VERSION ""

NS_ :

BS_:

BU_: VCU BMS INV ABS SENSOR_GATEWAY CHARGER DIAG RCM OCCUPANT_SENSOR

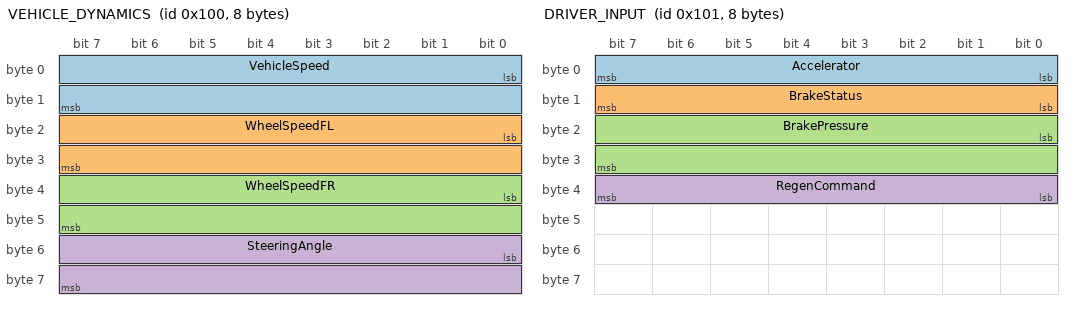
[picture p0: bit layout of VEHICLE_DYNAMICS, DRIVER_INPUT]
BO_ 256 VEHICLE_DYNAMICS: 8 ABS
 SG_ VehicleSpeed : 0|16@1+ (0.01,0) [0|655.35] "km/h" ABS
 SG_ WheelSpeedFL : 16|16@1+ (0.01,0) [0|655.35] "km/h" ABS
 SG_ WheelSpeedFR : 32|16@1+ (0.01,0) [0|655.35] "km/h" ABS
 SG_ SteeringAngle : 48|16@1- (0.1,0) [-3276.8|3276.7] "deg" ABS

BO_ 257 DRIVER_INPUT: 8 VCU
 SG_ Accelerator : 0|8@1+ (0.4,0) [0|100] "%" VCU
 SG_ BrakeStatus : 8|8@1+ (1,0) [0|1] "" VCU
 SG_ BrakePressure : 16|16@1+ (0.1,0) [0|6553.5] "bar" VCU
 SG_ RegenCommand : 32|8@1+ (0.4,0) [0|100] "%" VCU

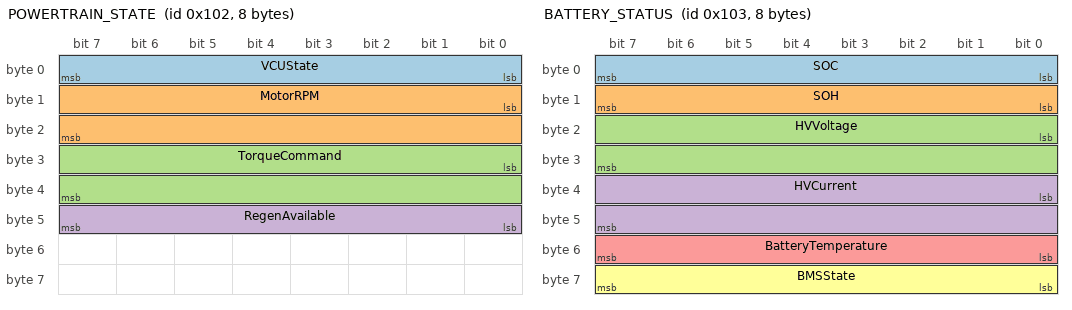
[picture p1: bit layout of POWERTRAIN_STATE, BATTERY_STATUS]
BO_ 258 POWERTRAIN_STATE: 8 VCU
 SG_ VCUState : 0|8@1+ (1,0) [0|255] "" VCU
 SG_ MotorRPM : 8|16@1+ (1,0) [0|65535] "rpm" VCU
 SG_ TorqueCommand : 24|16@1- (0.1,0) [-3276.8|3276.7] "Nm" VCU
 SG_ RegenAvailable : 40|8@1+ (1,0) [0|1] "" VCU

BO_ 259 BATTERY_STATUS: 8 BMS
 SG_ SOC : 0|8@1+ (0.4,0) [0|100] "%" BMS
 SG_ SOH : 8|8@1+ (0.4,0) [0|100] "%" BMS
 SG_ HVVoltage : 16|16@1+ (0.1,0) [0|1000] "V" BMS
 SG_ HVCurrent : 32|16@1- (0.1,0) [-3276.8|3276.7] "A" BMS
 SG_ BatteryTemperature : 48|8@1- (1,-40) [-40|215] "degC" BMS
 SG_ BMSState : 56|8@1+ (1,0) [0|255] "" BMS

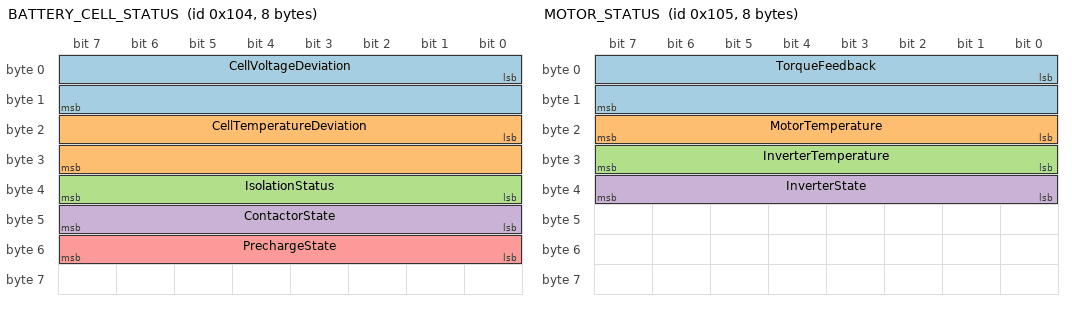
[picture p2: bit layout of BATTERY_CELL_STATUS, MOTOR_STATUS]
BO_ 260 BATTERY_CELL_STATUS: 8 BMS
 SG_ CellVoltageDeviation : 0|16@1+ (0.001,0) [0|65.535] "V" BMS
 SG_ CellTemperatureDeviation : 16|16@1+ (0.1,0) [0|6553.5] "degC" BMS
 SG_ IsolationStatus : 32|8@1+ (1,0) [0|3] "" BMS
 SG_ ContactorState : 40|8@1+ (1,0) [0|3] "" BMS
 SG_ PrechargeState : 48|8@1+ (1,0) [0|3] "" BMS

BO_ 261 MOTOR_STATUS: 8 INV
 SG_ TorqueFeedback : 0|16@1- (0.1,0) [-3276.8|3276.7] "Nm" INV
 SG_ MotorTemperature : 16|8@1- (1,-40) [-40|215] "degC" INV
 SG_ InverterTemperature : 24|8@1- (1,-40) [-40|215] "degC" INV
 SG_ InverterState : 32|8@1+ (1,0) [0|255] "" INV

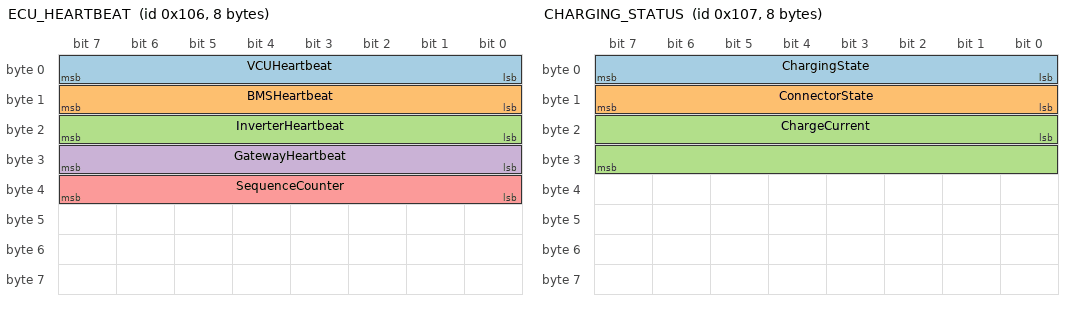
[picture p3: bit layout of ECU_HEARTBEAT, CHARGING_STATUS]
BO_ 262 ECU_HEARTBEAT: 8 VCU
 SG_ VCUHeartbeat : 0|8@1+ (1,0) [0|255] "" VCU
 SG_ BMSHeartbeat : 8|8@1+ (1,0) [0|255] "" BMS
 SG_ InverterHeartbeat : 16|8@1+ (1,0) [0|255] "" INV
 SG_ GatewayHeartbeat : 24|8@1+ (1,0) [0|255] "" SENSOR_GATEWAY
 SG_ SequenceCounter : 32|8@1+ (1,0) [0|255] "" VCU

BO_ 263 CHARGING_STATUS: 8 CHARGER
 SG_ ChargingState : 0|8@1+ (1,0) [0|255] "" CHARGER
 SG_ ConnectorState : 8|8@1+ (1,0) [0|3] "" CHARGER
 SG_ ChargeCurrent : 16|16@1+ (0.1,0) [0|6553.5] "A" CHARGER

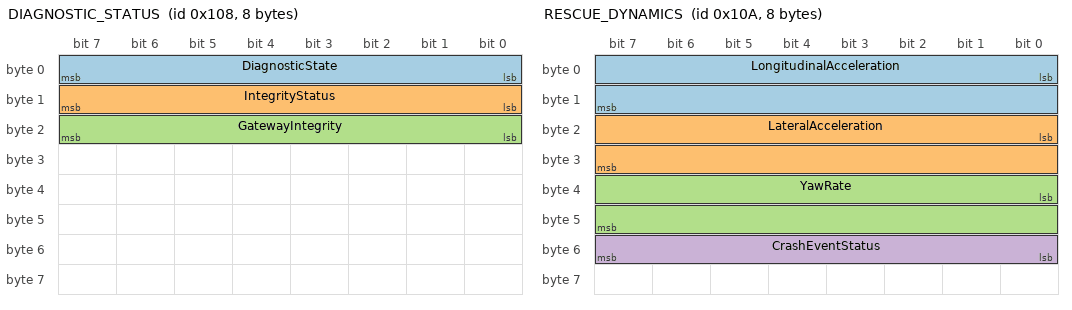
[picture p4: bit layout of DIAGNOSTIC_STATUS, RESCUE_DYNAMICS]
BO_ 264 DIAGNOSTIC_STATUS: 8 DIAG
 SG_ DiagnosticState : 0|8@1+ (1,0) [0|255] "" DIAG
 SG_ IntegrityStatus : 8|8@1+ (1,0) [0|3] "" DIAG
 SG_ GatewayIntegrity : 16|8@1+ (1,0) [0|3] "" DIAG

BO_ 265 AUXILIARY_POWER: 8 BMS
 SG_ AuxBatteryVoltage : 0|16@1+ (0.01,0) [0|655.35] "V" BMS
 SG_ AuxBatteryStatus : 16|8@1+ (1,0) [0|3] "" BMS

BO_ 266 RESCUE_DYNAMICS: 8 RCM
 SG_ LongitudinalAcceleration : 0|16@1- (0.01,0) [-327.68|327.67] "g" RCM
 SG_ LateralAcceleration : 16|16@1- (0.01,0) [-327.68|327.67] "g" RCM
 SG_ YawRate : 32|16@1- (0.1,0) [-3276.8|3276.7] "deg/s" RCM
 SG_ CrashEventStatus : 48|8@1+ (1,0) [0|3] "" RCM

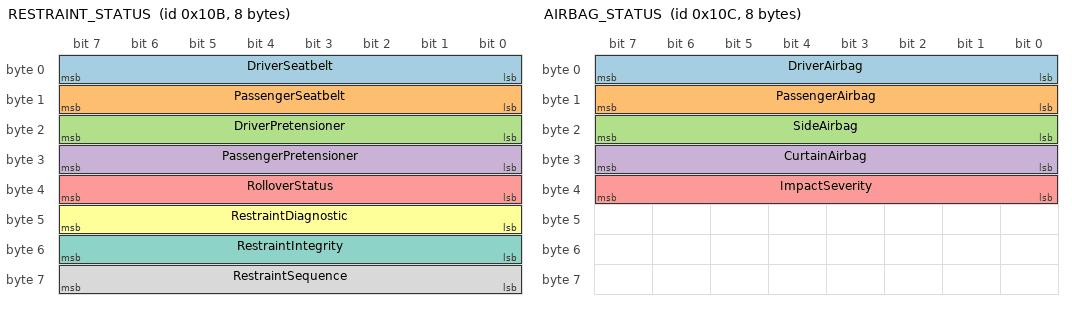
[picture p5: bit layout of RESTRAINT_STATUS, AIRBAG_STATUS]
BO_ 267 RESTRAINT_STATUS: 8 RCM
 SG_ DriverSeatbelt : 0|8@1+ (1,0) [0|3] "" RCM
 SG_ PassengerSeatbelt : 8|8@1+ (1,0) [0|3] "" RCM
 SG_ DriverPretensioner : 16|8@1+ (1,0) [0|3] "" RCM
 SG_ PassengerPretensioner : 24|8@1+ (1,0) [0|3] "" RCM
 SG_ RolloverStatus : 32|8@1+ (1,0) [0|3] "" RCM
 SG_ RestraintDiagnostic : 40|8@1+ (1,0) [0|255] "" RCM
 SG_ RestraintIntegrity : 48|8@1+ (1,0) [0|3] "" RCM
 SG_ RestraintSequence : 56|8@1+ (1,0) [0|255] "" RCM

BO_ 268 AIRBAG_STATUS: 8 RCM
 SG_ DriverAirbag : 0|8@1+ (1,0) [0|3] "" RCM
 SG_ PassengerAirbag : 8|8@1+ (1,0) [0|3] "" RCM
 SG_ SideAirbag : 16|8@1+ (1,0) [0|3] "" RCM
 SG_ CurtainAirbag : 24|8@1+ (1,0) [0|3] "" RCM
 SG_ ImpactSeverity : 32|8@1+ (1,0) [0|255] "" RCM

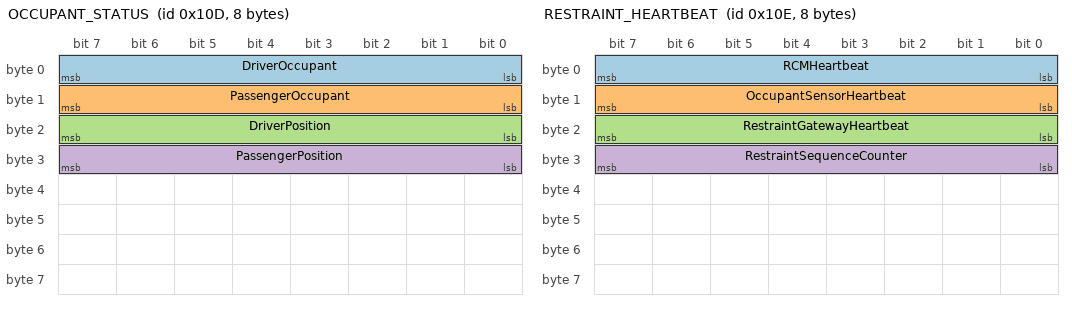
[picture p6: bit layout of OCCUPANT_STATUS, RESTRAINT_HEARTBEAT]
BO_ 269 OCCUPANT_STATUS: 8 OCCUPANT_SENSOR
 SG_ DriverOccupant : 0|8@1+ (1,0) [0|3] "" OCCUPANT_SENSOR
 SG_ PassengerOccupant : 8|8@1+ (1,0) [0|3] "" OCCUPANT_SENSOR
 SG_ DriverPosition : 16|8@1+ (1,0) [0|255] "" OCCUPANT_SENSOR
 SG_ PassengerPosition : 24|8@1+ (1,0) [0|255] "" OCCUPANT_SENSOR

BO_ 270 RESTRAINT_HEARTBEAT: 8 RCM
 SG_ RCMHeartbeat : 0|8@1+ (1,0) [0|255] "" RCM
 SG_ OccupantSensorHeartbeat : 8|8@1+ (1,0) [0|255] "" OCCUPANT_SENSOR
 SG_ RestraintGatewayHeartbeat : 16|8@1+ (1,0) [0|255] "" SENSOR_GATEWAY
 SG_ RestraintSequenceCounter : 24|8@1+ (1,0) [0|255] "" RCM
